# renode register map
Vendor: litex
Registers are 32-bit, read-write, reset 0x0 unless marked. A register's access mark holds for its fields unless they carry their own. Offsets are from the block's base; [hi:lo] are bit positions; {n}, {i} and the like mark numbered series.

## SPINOR
Base 0xF0014000
0x00 CONFIG reset 0xA
  [4:0] dummy — Number of dummy cycles
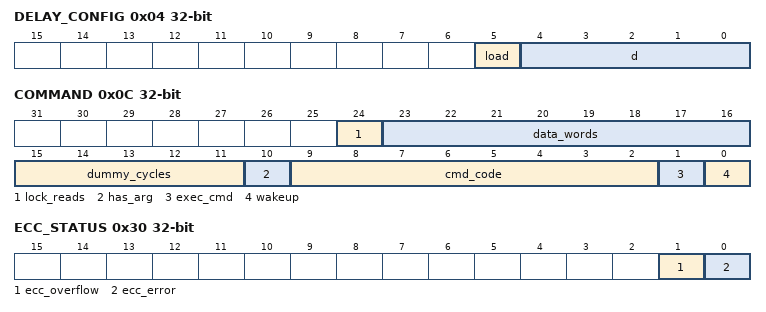
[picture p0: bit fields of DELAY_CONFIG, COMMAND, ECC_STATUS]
0x04 DELAY_CONFIG
  [5] load — Force delay taps to delay_d
  [4:0] d — Delay amount; each increment is 78ps
0x08 DELAY_STATUS
  [4:0] q — Readback of current delay amount, useful if inc/ce is used to set
0x0C COMMAND — Write individual bits to issue special commands to SPI; setting multiple bits at once leads to undefined behavior.
  [24] lock_reads — When set, locks out read operations (recommended when doing programming)
  [23:16] data_words — Number of data words (2x bytes)
  [15:11] dummy_cycles — Number of dummy cycles for manual command; 0 implies a write, >0 implies read
  [10] has_arg — When set, transmits the value of `cmd_arg` as the argument to the command
  [9:2] cmd_code — Manual command code (first 8 bits, e.g. PP4B is 0x12)
  [1] exec_cmd — Writing a `1` executes a manual command
  [0] wakeup — Sequence through init & wakeup routine
0x10 CMD_ARG — Command argument
  [31:0] cmd_arg — Argument to manual command
0x14 CMD_RBK_DATA — Readback data from commands
  [31:0] cmd_rbk_data — Data read back from a cmd_code that has `write_code` set to 0
0x18 STATUS — Interface status
  [0] wip — Operation in progress (write or erease)
0x1C WDATA — Page data to write to FLASH
  [15:0] wdata — 16-bit wide write data presented to FLASH, committed to a 128-entry deep FIFO. Writes to this register are not cached; note that writes to the SPINOR address space are also committed to the FIFO, but this space is cached by the CPU, and therefore not guaranteed to be coherent or in order. The direct wishbone-write address space is provisioned for e.g. USB bus masters that don't have caching.
0x20 EV_STATUS — An ECC event has happened on the current block; triggered by falling edge of ECC_N
  [0] ecc_error — Level of the ``ecc_error`` event
0x24 EV_PENDING — An ECC event has happened on the current block; triggered by falling edge of ECC_N
  [0] ecc_error
0x28 EV_ENABLE — An ECC event has happened on the current block; triggered by falling edge of ECC_N
  [0] ecc_error — Write a ``1`` to enable the ``ecc_error`` Event
0x2C ECC_ADDRESS
  [31:0] ecc_address — Address of the most recent ECC event
0x30 ECC_STATUS
  [1] ecc_overflow — More than one ECS_N event has happened since th last time ecc_address was checked
  [0] ecc_error — Live status of the ECS_N bit (ECC error on current packet when low)

## KEYBOARD
Base 0xF0015000
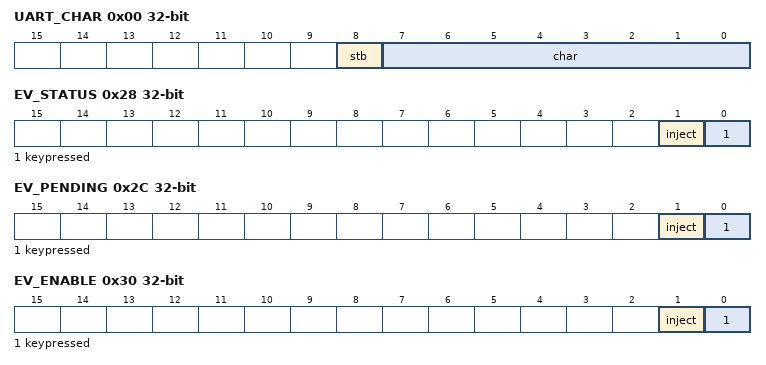
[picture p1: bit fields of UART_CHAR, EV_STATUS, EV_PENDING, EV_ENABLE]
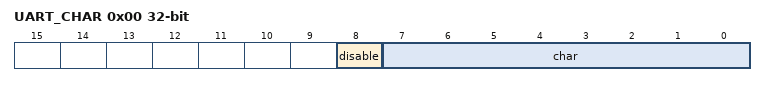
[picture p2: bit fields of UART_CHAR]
0x00 UART_CHAR
  [8] stb — current strobe value (for debugging)
  [7:0] char — character value being injected
{0x4+4i} ROW{i}DAT (i=0..8) — Column data for the given row
  [9:0] row{i}dat
0x28 EV_STATUS — Key injection request received
  [1] inject — Level of the ``inject`` event
  [0] keypressed — Level of the ``keypressed`` event
0x2C EV_PENDING — Key injection request received
  [1] inject — Key injection request received
  [0] keypressed — Triggered every time there is a difference in the row state
0x30 EV_ENABLE — Key injection request received
  [1] inject — Write a ``1`` to enable the ``inject`` Event
  [0] keypressed — Write a ``1`` to enable the ``keypressed`` Event
0x34 ROWCHANGE — The rows that changed at the point of interrupt generation. Does not update again until the interrupt is serviced.
  [8:0] rowchange

## KEYINJECT
Base 0xF0016000
0x00 UART_CHAR
  [8] disable — writing a 1 permanently disables the block, until the next cold boot
  [7:0] char — character value to inject. Automatically raises an interrupt upon write. There is no interlock or FIFO buffering on this, so you can lose characters if you inject too fast.

## SEED
Base 0xF0017000
0x00 SEED1 reset 0xD1CE410 — Bits 32-63 of `SEED_SEED`. Seed used for the build
  [31:0] seed
0x04 SEED0 reset 0x23175A86 — Bits 0-31 of `SEED_SEED`.
  [31:0] seed
